# ATtiny2313A register map
Vendor: Atmel; File version: 1.0
CPU: other r0p0, little endian, no MPU, no FPU, 4 interrupt priority bits
Registers are 8-bit, read-write, reset 0x0 unless marked. A register's access mark holds for its fields unless they carry their own. Offsets are from the block's base; [hi:lo] are bit positions.

## LOCKBIT — Lockbits
Base 0x00000000
0x00 LOCKBIT
  [1:0] LB — Memory Lock
    0=PROG_VER_DISABLED (Further programming and verification disabled); 2=PROG_DISABLED (Further programming disabled); 3=NO_LOCK (No memory lock features enabled)

## PORTA — I/O Port
Base 0x00000039
0x00 PINA — Port A Input Pins
0x01 DDRA — Port A Data Direction Register
0x02 PORTA — Port A Data Register

## PORTB — I/O Port
Base 0x00000036
0x00 PINB — Port B Input Pins
0x01 DDRB — Port B Data Direction Register
0x02 PORTB — Port B Data Register

## PORTD — I/O Port
Base 0x00000030
0x00 PIND — Input Pins, Port D
0x01 DDRD — Data Direction Register, Port D
0x02 PORTD — Data Register, Port D

## TC0 — Timer/Counter, 8-bit
Base 0x00000050
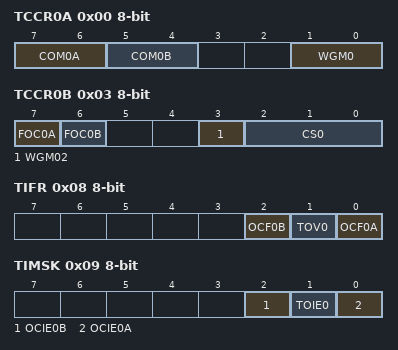
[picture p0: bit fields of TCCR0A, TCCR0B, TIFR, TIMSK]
0x00 TCCR0A — Timer/Counter Control Register A
  [7:6] COM0A — Compare Match Output A Mode
  [5:4] COM0B — Compare Match Output B Mode
  [1:0] WGM0 — Waveform Generation Mode
0x02 TCNT0 — Timer/Counter0
0x03 TCCR0B — Timer/Counter Control Register B
  [7] FOC0A — Force Output Compare B
  [6] FOC0B — Force Output Compare B
  [3] WGM02
  [2:0] CS0 — Clock Select
    0=No Clock Source (Stopped); 1=Running, No Prescaling; 2=Running, CLK/8; 3=Running, CLK/64; 4=Running, CLK/256; 5=Running, CLK/1024; 6=Running, ExtClk Tx Falling Edge; 7=Running, ExtClk Tx Rising Edge
0x06 OCR0A — Timer/Counter0 Output Compare Register
0x08 TIFR — Timer/Counter Interrupt Flag register
  [2] OCF0B — Timer/Counter0 Output Compare Flag 0B
  [1] TOV0 — Timer/Counter0 Overflow Flag
  [0] OCF0A — Timer/Counter0 Output Compare Flag 0A
0x09 TIMSK — Timer/Counter Interrupt Mask Register
  [2] OCIE0B — Timer/Counter0 Output Compare Match B Interrupt Enable
  [1] TOIE0 — Timer/Counter0 Overflow Interrupt Enable
  [0] OCIE0A — Timer/Counter0 Output Compare Match A Interrupt Enable
0x0C OCR0B — Timer/Counter0 Output Compare Register

## TC1 — Timer/Counter, 16-bit
Base 0x00000042
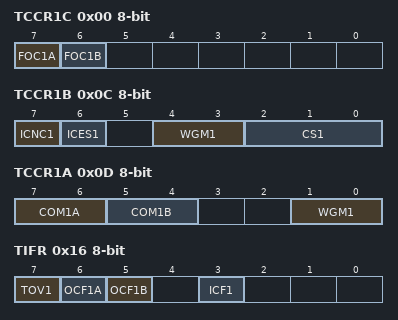
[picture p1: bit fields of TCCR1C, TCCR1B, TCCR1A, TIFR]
0x00 TCCR1C — Timer/Counter1 Control Register C
  [7] FOC1A — Force Output Compare for Channel A
  [6] FOC1B — Force Output Compare for Channel B
0x02 ICR1 16-bit (reset mask 0xFF) — Timer/Counter1 Input Capture Register Bytes
0x06 OCR1B 16-bit (reset mask 0xFF) — Timer/Counter1 Output Compare Register Bytes
0x08 OCR1A 16-bit (reset mask 0xFF) — Timer/Counter1 Output Compare Register Bytes
0x0A TCNT1 16-bit (reset mask 0xFF) — Timer/Counter1 Bytes
0x0C TCCR1B — Timer/Counter1 Control Register B
  [7] ICNC1 — Input Capture 1 Noise Canceler
  [6] ICES1 — Input Capture 1 Edge Select
  [4:3] WGM1 — Waveform Generation Mode Bits
  [2:0] CS1 — Clock Select1 bits
    0=No Clock Source (Stopped); 1=Running, No Prescaling; 2=Running, CLK/8; 3=Running, CLK/64; 4=Running, CLK/256; 5=Running, CLK/1024; 6=Running, ExtClk Tx Falling Edge; 7=Running, ExtClk Tx Rising Edge
0x0D TCCR1A — Timer/Counter1 Control Register A
  [7:6] COM1A — Compare Output Mode 1A, bits
  [5:4] COM1B — Compare Output Mode 1B, bits
  [1:0] WGM1 — Pulse Width Modulator Select Bits
0x16 TIFR — Timer/Counter Interrupt Flag register
  [7] TOV1 — Timer/Counter1 Overflow Flag
  [6] OCF1A — Output Compare Flag 1A
  [5] OCF1B — Output Compare Flag 1B
  [3] ICF1 — Input Capture Flag 1
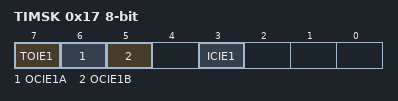
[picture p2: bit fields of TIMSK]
0x17 TIMSK — Timer/Counter Interrupt Mask Register
  [7] TOIE1 — Timer/Counter1 Overflow Interrupt Enable
  [6] OCIE1A — Timer/Counter1 Output CompareA Match Interrupt Enable
  [5] OCIE1B — Timer/Counter1 Output CompareB Match Interrupt Enable
  [3] ICIE1 — Timer/Counter1 Input Capture Interrupt Enable

## USART
Base 0x00000022
0x00 UBRRH — USART Baud Rate Register High Byte
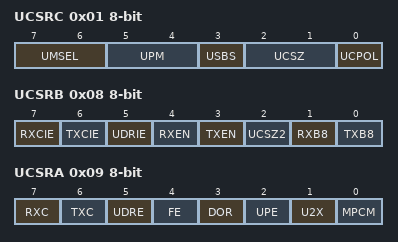
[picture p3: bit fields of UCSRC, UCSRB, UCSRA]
0x01 UCSRC — USART Control and Status Register C
  [7:6] UMSEL — USART Mode Select
    0=Asynchronous Operation; 1=Synchronous Operation; 3=Master SPI
  [5:4] UPM — Parity Mode Bits
    0=Disabled; 2=Enabled, Even Parity; 3=Enabled, Odd Parity
  [3] USBS — Stop Bit Select
    0=1-bit; 1=2-bit
  [2:1] UCSZ — Character Size Bits
  [0] UCPOL — Clock Polarity
0x07 UBRRL — USART Baud Rate Register Low Byte
0x08 UCSRB — USART Control and Status Register B
  [7] RXCIE — RX Complete Interrupt Enable
  [6] TXCIE — TX Complete Interrupt Enable
  [5] UDRIE — USART Data register Empty Interrupt Enable
  [4] RXEN — Receiver Enable
  [3] TXEN — Transmitter Enable
  [2] UCSZ2 — Character Size
  [1] RXB8 — Receive Data Bit 8
  [0] TXB8 — Transmit Data Bit 8
0x09 UCSRA — USART Control and Status Register A
  [7] RXC — USART Receive Complete
  [6] TXC — USART Transmitt Complete
  [5] UDRE — USART Data Register Empty
  [4] FE — Framing Error
  [3] DOR — Data overRun
  [2] UPE — USART Parity Error
  [1] U2X — Double the USART Transmission Speed
  [0] MPCM — Multi-processor Communication Mode
0x0A UDR — USART I/O Data Register

## USI — Universal Serial Interface
Base 0x0000002D
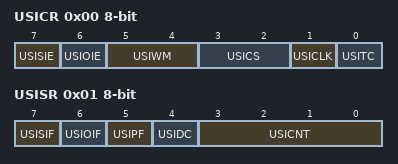
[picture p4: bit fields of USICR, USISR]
0x00 USICR — USI Control Register
  [7] USISIE — Start Condition Interrupt Enable
  [6] USIOIE — Counter Overflow Interrupt Enable
  [5:4] USIWM — USI Wire Mode Bits
    0=Normal Operation; 1=Three-Wire Mode; 2=Two-Wire Mode; 3=Two-Wire Mode Held Low
  [3:2] USICS — USI Clock Source Select Bits
  [1] USICLK — Clock Strobe
  [0] USITC — Toggle Clock Port Pin
0x01 USISR — USI Status Register
  [7] USISIF — Start Condition Interrupt Flag
  [6] USIOIF — Counter Overflow Interrupt Flag
  [5] USIPF — Stop Condition Flag
  [4] USIDC — Data Output Collision
  [3:0] USICNT — USI Counter Value Bits
0x02 USIDR — USI Data Register

## WDT — Watchdog Timer
Base 0x00000041
0x00 WDTCR — Watchdog Timer Control Register
  [7] WDIF — Watchdog Timeout Interrupt Flag
  [6] WDIE — Watchdog Timeout Interrupt Enable
  [4] WDCE — Watchdog Change Enable
  [3] WDE — Watch Dog Enable
  [5:0] WDP — Watchdog Timer Prescaler Bits
    0=Oscillator Cycles 2K; 1=Oscillator Cycles 4K; 2=Oscillator Cycles 8K; 3=Oscillator Cycles 16K; 4=Oscillator Cycles 32K; 5=Oscillator Cycles 64K; 6=Oscillator Cycles 128K; 7=Oscillator Cycles 256K
